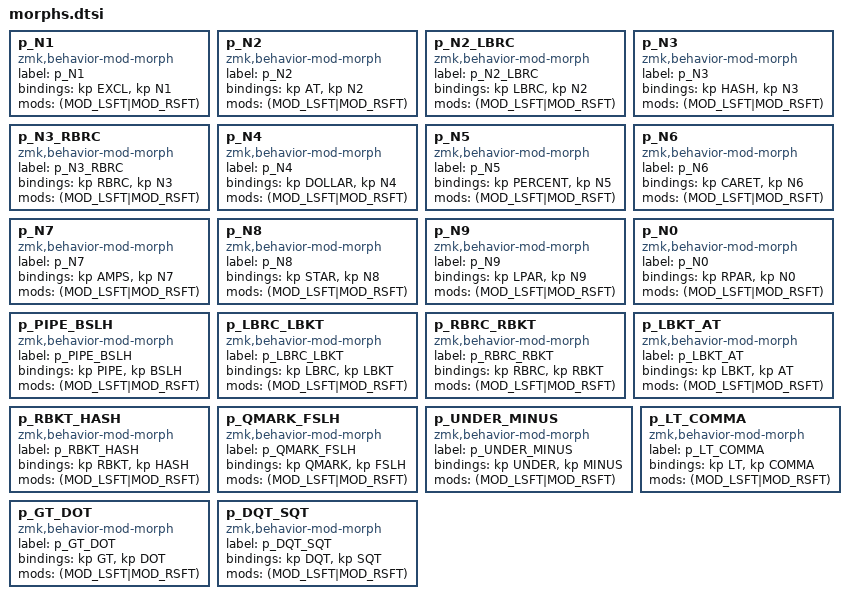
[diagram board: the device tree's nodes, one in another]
p_N1: p_N1 {
    compatible = "zmk,behavior-mod-morph";
    label = "p_N1";
    #binding-cells = <0>;
    bindings = <&kp EXCL>, <&kp N1>;
    mods = <(MOD_LSFT|MOD_RSFT)>;
};

p_N2: p_N2 {
    compatible = "zmk,behavior-mod-morph";
    label = "p_N2";
    #binding-cells = <0>;
    bindings = <&kp AT>, <&kp N2>;
    mods = <(MOD_LSFT|MOD_RSFT)>;
};

p_N2_LBRC: p_N2_LBRC {
    compatible = "zmk,behavior-mod-morph";
    label = "p_N2_LBRC";
    #binding-cells = <0>;
    bindings = <&kp LBRC>, <&kp N2>;
    mods = <(MOD_LSFT|MOD_RSFT)>;
};

p_N3: p_N3 {
    compatible = "zmk,behavior-mod-morph";
    label = "p_N3";
    #binding-cells = <0>;
    bindings = <&kp HASH>, <&kp N3>;
    mods = <(MOD_LSFT|MOD_RSFT)>;
};


p_N3_RBRC: p_N3_RBRC {
    compatible = "zmk,behavior-mod-morph";
    label = "p_N3_RBRC";
    #binding-cells = <0>;
    bindings = <&kp RBRC>, <&kp N3>;
    mods = <(MOD_LSFT|MOD_RSFT)>;
};

p_N4: p_N4 {
    compatible = "zmk,behavior-mod-morph";
    label = "p_N4";
    #binding-cells = <0>;
    bindings = <&kp DOLLAR>, <&kp N4>;
    mods = <(MOD_LSFT|MOD_RSFT)>;
};

p_N5: p_N5 {
    compatible = "zmk,behavior-mod-morph";
    label = "p_N5";
    #binding-cells = <0>;
    bindings = <&kp PERCENT>, <&kp N5>;
    mods = <(MOD_LSFT|MOD_RSFT)>;
};

p_N6: p_N6 {
    compatible = "zmk,behavior-mod-morph";
    label = "p_N6";
    #binding-cells = <0>;
    bindings = <&kp CARET>, <&kp N6>;
    mods = <(MOD_LSFT|MOD_RSFT)>;
};

p_N7: p_N7 {
    compatible = "zmk,behavior-mod-morph";
    label = "p_N7";
    #binding-cells = <0>;
    bindings = <&kp AMPS>, <&kp N7>;
    mods = <(MOD_LSFT|MOD_RSFT)>;
};

p_N8: p_N8 {
    compatible = "zmk,behavior-mod-morph";
    label = "p_N8";
    #binding-cells = <0>;
    bindings = <&kp STAR>, <&kp N8>;
    mods = <(MOD_LSFT|MOD_RSFT)>;
};

p_N9: p_N9 {
    compatible = "zmk,behavior-mod-morph";
    label = "p_N9";
    #binding-cells = <0>;
    bindings = <&kp LPAR>, <&kp N9>;
    mods = <(MOD_LSFT|MOD_RSFT)>;
};

p_N0: p_N0 {
    compatible = "zmk,behavior-mod-morph";
    label = "p_N0";
    #binding-cells = <0>;
    bindings = <&kp RPAR>, <&kp N0>;
    mods = <(MOD_LSFT|MOD_RSFT)>;
};

p_N0: p_N0 {
    compatible = "zmk,behavior-mod-morph";
    label = "p_N0";
    #binding-cells = <0>;
    bindings = <&kp RPAR>, <&kp N0>;
    mods = <(MOD_LSFT|MOD_RSFT)>;
};

p_PIPE_BSLH: p_PIPE_BSLH {
    compatible = "zmk,behavior-mod-morph";
    label = "p_PIPE_BSLH";
    #binding-cells = <0>;
    bindings = <&kp PIPE>, <&kp BSLH>;
    mods = <(MOD_LSFT|MOD_RSFT)>;
};

p_LBRC_LBKT: p_LBRC_LBKT {
    compatible = "zmk,behavior-mod-morph";
    label = "p_LBRC_LBKT";
    #binding-cells = <0>;
    bindings = <&kp LBRC>, <&kp LBKT>;
    mods = <(MOD_LSFT|MOD_RSFT)>;
};

p_RBRC_RBKT: p_RBRC_RBKT {
    compatible = "zmk,behavior-mod-morph";
    label = "p_RBRC_RBKT";
    #binding-cells = <0>;
    bindings = <&kp RBRC>, <&kp RBKT>;
    mods = <(MOD_LSFT|MOD_RSFT)>;
};

p_LBKT_AT: p_LBKT_AT {
    compatible = "zmk,behavior-mod-morph";
    label = "p_LBKT_AT";
    #binding-cells = <0>;
    bindings = <&kp LBKT>, <&kp AT>;
    mods = <(MOD_LSFT|MOD_RSFT)>;
};

p_RBKT_HASH: p_RBKT_HASH {
    compatible = "zmk,behavior-mod-morph";
    label = "p_RBKT_HASH";
    #binding-cells = <0>;
    bindings = <&kp RBKT>, <&kp HASH>;
    mods = <(MOD_LSFT|MOD_RSFT)>;
};

p_QMARK_FSLH: p_QMARK_FSLH {
    compatible = "zmk,behavior-mod-morph";
    label = "p_QMARK_FSLH";
    #binding-cells = <0>;
    bindings = <&kp QMARK>, <&kp FSLH>;
    mods = <(MOD_LSFT|MOD_RSFT)>;
};

p_UNDER_MINUS: p_UNDER_MINUS {
    compatible = "zmk,behavior-mod-morph";
    label = "p_UNDER_MINUS";
    #binding-cells = <0>;
    bindings = <&kp UNDER>, <&kp MINUS>;
    mods = <(MOD_LSFT|MOD_RSFT)>;
};

p_LT_COMMA: p_LT_COMMA {
    compatible = "zmk,behavior-mod-morph";
    label = "p_LT_COMMA";
    #binding-cells = <0>;
    bindings = <&kp LT>, <&kp COMMA>;
    mods = <(MOD_LSFT|MOD_RSFT)>;
};

p_GT_DOT: p_GT_DOT {
    compatible = "zmk,behavior-mod-morph";
    label = "p_GT_DOT";
    #binding-cells = <0>;
    bindings = <&kp GT>, <&kp DOT>;
    mods = <(MOD_LSFT|MOD_RSFT)>;
};

p_DQT_SQT: p_DQT_SQT {
    compatible = "zmk,behavior-mod-morph";
    label = "p_DQT_SQT";
    #binding-cells = <0>;
    bindings = <&kp DQT>, <&kp SQT>;
    mods = <(MOD_LSFT|MOD_RSFT)>;
};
